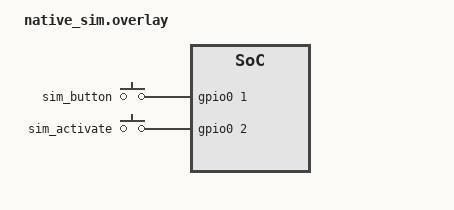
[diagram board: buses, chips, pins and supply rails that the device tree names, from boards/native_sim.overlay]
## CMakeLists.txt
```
cmake_minimum_required(VERSION 3.20.0)

find_package(Zephyr REQUIRED HINTS $ENV{ZEPHYR_BASE})
project(cmf_watch_simulator)

target_include_directories(app PRIVATE src)

target_sources(app PRIVATE
  src/main.c
  src/platform/watch_platform_native.c
  src/runtime/watch_runtime.c
  src/actions/watch_actions.c
  src/apps/app_registry.c
  src/navigation/navigation.c
  src/renderer/renderer.c
  src/input/watch_input.c
  src/input/watch_gesture.c
  src/state/watch_state.c
  src/state/watch_sync.c
  src/animation/watch_animation.c
  src/cache/watch_cache.c
  src/cache/watch_cache_storage.c
  src/protocol/watch_protocol.c
  src/transport/transport.c
)
```

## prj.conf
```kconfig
CONFIG_MAIN_STACK_SIZE=8192
CONFIG_HEAP_MEM_POOL_SIZE=32768

CONFIG_DISPLAY=y
CONFIG_DISPLAY_LOG_LEVEL_ERR=y
CONFIG_INPUT=y
CONFIG_GPIO=y

CONFIG_LVGL=y
CONFIG_LV_Z_MEM_POOL_SIZE=65536
CONFIG_LV_COLOR_FORMAT_XRGB8888=y
CONFIG_LV_DEF_REFR_PERIOD=16
CONFIG_LV_USE_LOG=y
CONFIG_LV_USE_LABEL=y
CONFIG_LV_USE_BUTTON=y
CONFIG_LV_FONT_MONTSERRAT_14=y
CONFIG_LV_FONT_MONTSERRAT_20=y
CONFIG_LV_FONT_MONTSERRAT_28=y
CONFIG_LV_FONT_UNSCII_16=y

CONFIG_LOG=y
CONFIG_LOG_DEFAULT_LEVEL=3
CONFIG_JSON_LIBRARY=y
```

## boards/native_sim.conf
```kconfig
CONFIG_LV_COLOR_FORMAT_XRGB8888=y
CONFIG_GPIO=y
# The active native/64 target uses native_sim_native_64.conf.
```

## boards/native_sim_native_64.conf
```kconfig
CONFIG_LV_COLOR_FORMAT_XRGB8888=y
CONFIG_GPIO=y
CONFIG_NETWORKING=y
CONFIG_NET_DRIVERS=y
CONFIG_NET_SOCKETS=y
CONFIG_NET_SOCKETS_OFFLOAD=y
CONFIG_NET_NATIVE_OFFLOADED_SOCKETS=y
CONFIG_ETH_NATIVE_TAP=n
```

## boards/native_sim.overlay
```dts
/* CMF Watch Pro 2 desktop simulator: round 466 x 466 pixel display. */

#include <zephyr/dt-bindings/input/input-event-codes.h>

/ {
	aliases {
		sw0 = &sim_button;
		sw1 = &sim_activate;
	};

	keys {
		compatible = "gpio-keys";

		sim_button: sim_button {
			gpios = <&gpio0 1 GPIO_ACTIVE_HIGH>;
			zephyr,code = <INPUT_KEY_R>;
		};

		sim_activate: sim_activate {
			gpios = <&gpio0 2 GPIO_ACTIVE_HIGH>;
			zephyr,code = <INPUT_KEY_P>;
		};
	};
};

&sdl_dc {
	width = <466>;
	height = <466>;
};

&gpio0 {
	ngpios = <3>;

	sdl_gpio {
		status = "okay";
		compatible = "zephyr,gpio-emul-sdl";
		/* SDL scancode 19 is P; 21 is R. */
		scancodes = <0 21 19>;
	};
};
```

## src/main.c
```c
/* SPDX-License-Identifier: Apache-2.0 */
#include "runtime/watch_runtime.h"

int main(void)
{
	return watch_runtime_run();
}
```
